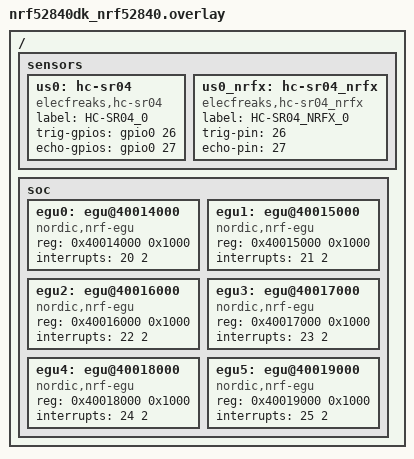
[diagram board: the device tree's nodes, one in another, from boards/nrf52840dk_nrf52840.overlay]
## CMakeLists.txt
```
cmake_minimum_required(VERSION 3.13.1)

find_package(Zephyr REQUIRED HINTS $ENV{ZEPHYR_BASE})
project(hc_sr04)

FILE(GLOB app_sources src/*.c)
target_sources(app PRIVATE ${app_sources})
target_include_directories(app PRIVATE include)
```

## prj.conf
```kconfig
# Logging
CONFIG_USE_SEGGER_RTT=y
CONFIG_RTT_CONSOLE=n
CONFIG_UART_CONSOLE=n
CONFIG_CONSOLE=n
CONFIG_STDOUT_CONSOLE=n
CONFIG_PRINTK=n
CONFIG_EARLY_CONSOLE=n

# Drivers and peripherals
CONFIG_I2C=n
CONFIG_WATCHDOG=n
CONFIG_PINMUX=n
CONFIG_SPI=n
CONFIG_SERIAL=n
CONFIG_NFCT_PINS_AS_GPIOS=y

# Power management
CONFIG_SYS_POWER_MANAGEMENT=y

# Interrupts
CONFIG_DYNAMIC_INTERRUPTS=n
CONFIG_IRQ_OFFLOAD=n

# Memory protection
CONFIG_THREAD_CUSTOM_DATA=n
CONFIG_FPU=n

# Boot
CONFIG_BOOT_BANNER=n
CONFIG_BOOT_DELAY=0

# Unneeded features
CONFIG_TIMESLICING=n
CONFIG_MINIMAL_LIBC_MALLOC=n

# Sensor
CONFIG_SENSOR=y
CONFIG_GPIO=n
CONFIG_HC_SR04=n
CONFIG_HC_SR04_NRFX=y

# Build
CONFIG_ASSERT=y
CONFIG_SIZE_OPTIMIZATIONS=y
CONFIG_LOG=y
CONFIG_DEBUG=y
```

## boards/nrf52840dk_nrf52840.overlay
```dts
/ {

    sensors {

        us0: hc-sr04 {
            compatible = "elecfreaks,hc-sr04";
            label = "HC-SR04_0";
            trig-gpios = <&gpio0 26 GPIO_ACTIVE_HIGH>;
            echo-gpios = <&gpio0 27 GPIO_ACTIVE_HIGH>;
            status = "okay";
        };
    
        us0_nrfx: hc-sr04_nrfx {
            compatible = "elecfreaks,hc-sr04_nrfx";
            label = "HC-SR04_NRFX_0";
            trig-pin = <26>;
            echo-pin = <27>;
            status = "okay";
        };
    };

    soc {

        egu0: egu@40014000 {
                compatible = "nordic,nrf-egu";
                reg = <0x40014000 0x1000>;
                interrupts = <20 2>;
                status = "okay";
        };

        egu1: egu@40015000 {
                compatible = "nordic,nrf-egu";
                reg = <0x40015000 0x1000>;
                interrupts = <21 2>;
                status = "okay";
        };

        egu2: egu@40016000 {
                compatible = "nordic,nrf-egu";
                reg = <0x40016000 0x1000>;
                interrupts = <22 2>;
                status = "okay";
        };

        egu3: egu@40017000 {
                compatible = "nordic,nrf-egu";
                reg = <0x40017000 0x1000>;
                interrupts = <23 2>;
                status = "okay";
        };

        egu4: egu@40018000 {
                compatible = "nordic,nrf-egu";
                reg = <0x40018000 0x1000>;
                interrupts = <24 2>;
                status = "okay";
        };

        egu5: egu@40019000 {
                compatible = "nordic,nrf-egu";
                reg = <0x40019000 0x1000>;
                interrupts = <25 2>;
                status = "okay";
        };
    };
};
```

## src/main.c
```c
/*
 * Copyright (c) 2020 Daniel Veilleux
 *
 * SPDX-License-Identifier: Apache-2.0
 */

#include <kernel.h>
#include <string.h>
#include <zephyr.h>
#include <device.h>
#include <drivers/sensor.h>
#include <stdio.h>
#include <sys/__assert.h>

#include <logging/log.h>
LOG_MODULE_REGISTER(main, LOG_LEVEL_DBG);

K_TIMER_DEFINE(sync_timer, NULL, NULL);


static int measure(const struct device *dev)
{
    int ret;
    struct sensor_value distance;

    ret = sensor_sample_fetch_chan(dev, SENSOR_CHAN_ALL);
    switch (ret) {
    case 0:
        ret = sensor_channel_get(dev, SENSOR_CHAN_DISTANCE, &distance);
        if (ret) {
            LOG_ERR("sensor_channel_get failed ret %d", ret);
            return ret;
        }
        LOG_INF("%s: %d.%03dM", dev->name, distance.val1, (distance.val2 / 1000));
        break;
    case -EIO:
        LOG_WRN("%s: Could not read device", dev->name);
        break;
    default:
        LOG_ERR("Error when reading device: %s", dev->name);
        break;
    }
    return 0;
}

void main(void)
{
    int ret;
    const struct device *dev;

    if (IS_ENABLED(CONFIG_LOG_BACKEND_RTT)) {
        /* Give RTT log time to be flushed before executing tests */
        k_sleep(K_MSEC(500));
    }

#if CONFIG_HC_SR04
    dev = device_get_binding("HC-SR04_0");
#else
    dev = device_get_binding("HC-SR04_NRFX_0");
#endif

    if (dev == NULL) {
        LOG_ERR("Failed to get dev binding");
        return;
    }
    LOG_INF("dev is %p, name is %s", dev, dev->name);
    k_timer_start(&sync_timer, K_MSEC(25), K_MSEC(25));
    while (1) {
        k_timer_status_sync(&sync_timer);
        ret = measure(dev);
        if (ret) {
            return;
        }
    }
    LOG_INF("exiting");
}
```
